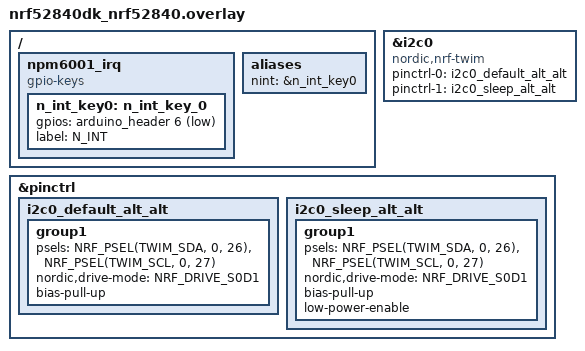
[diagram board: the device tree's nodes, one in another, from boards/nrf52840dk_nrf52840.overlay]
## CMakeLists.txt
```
#
# Copyright (c) 2022 Nordic Semiconductor
#
# SPDX-License-Identifier: LicenseRef-Nordic-5-Clause
#

cmake_minimum_required(VERSION 3.20.0)

find_package(Zephyr REQUIRED HINTS $ENV{ZEPHYR_BASE})
project(NONE)

# NORDIC SDK APP START
target_sources(app PRIVATE
  src/main.c
)
# NORDIC SDK APP END

target_sources_ifdef(CONFIG_SHELL
  app PRIVATE src/sample_shell_cmds.c)
```

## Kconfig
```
#
# Copyright (c) 2022 Nordic Semiconductor ASA
#
# SPDX-License-Identifier: LicenseRef-Nordic-5-Clause
#

menu "Zephyr Kernel"
source "Kconfig.zephyr"
endmenu

menu "nPM6001 sample options"
module = MAIN
module-str = Sample application
source "${ZEPHYR_BASE}/subsys/logging/Kconfig.template.log_config"
endmenu
```

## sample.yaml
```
sample:
  description: nPM6001 sample
  name: npm6001
common:
  integration_platforms:
      - nrf52840dk_nrf52840
      - nrf52dk_nrf52832
      - nrf5340dk_nrf5340_cpuapp
      - nrf5340dk_nrf5340_cpuapp_ns
  platform_allow: nrf52840dk_nrf52840 nrf52dk_nrf52832
    nrf5340dk_nrf5340_cpuapp nrf5340dk_nrf5340_cpuapp_ns
  tags: npm6001 ci_build

tests:
  sample.app_npm6001:
    build_only: true
  sample.app_npm6001_loopback:
    build_only: false
    harness: console
    harness_config:
      ordered: false
      regex:
        - ".*nPM6001 successfully initialized..*"
      type: multi_line
    extra_args: CONFIG_TEST=y
    integration_platforms:
        - nrf52840dk_nrf52840
        - nrf5340dk_nrf5340_cpuapp
```

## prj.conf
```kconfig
#
# Copyright (c) 2022 Nordic Semiconductor
#
# SPDX-License-Identifier: LicenseRef-Nordic-5-Clause
#

# Enable I2C ("TWI")
CONFIG_I2C=y

# Enable nPM6001 library
CONFIG_LIB_NPM6001=y
# Needed for certain nPM6001-EK revisions
CONFIG_LIB_NPM6001_C3_WORKAROUND=y

# Enable logging
CONFIG_LOG=y

# Enable Shell
CONFIG_SHELL=y

# Enable DK LED and Buttons library
CONFIG_DK_LIBRARY=y
CONFIG_GPIO=y
```

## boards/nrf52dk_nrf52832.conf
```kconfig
#
# Copyright (c) 2022 Nordic Semiconductor
#
# SPDX-License-Identifier: LicenseRef-Nordic-5-Clause
#

# Disable Shell
# (nRF52-DK not suitable for using COM port and external power supply simultaneously)
CONFIG_SHELL=n
```

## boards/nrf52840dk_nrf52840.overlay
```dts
i2c0: &i2c0 {
	compatible = "nordic,nrf-twim";
	status = "okay";

	pinctrl-0 = <&i2c0_default_alt_alt>;
	pinctrl-1 = <&i2c0_sleep_alt_alt>;
	pinctrl-names = "default", "sleep";
};

&pinctrl {
	i2c0_default_alt_alt: i2c0_default_alt_alt {
		group1 {
			psels = <NRF_PSEL(TWIM_SDA, 0, 26)>,
				<NRF_PSEL(TWIM_SCL, 0, 27)>;
			nordic,drive-mode = <NRF_DRIVE_S0D1>;
			bias-pull-up;
		};
	};

	i2c0_sleep_alt_alt: i2c0_sleep_alt_alt {
		group1 {
			psels = <NRF_PSEL(TWIM_SDA, 0, 26)>,
				<NRF_PSEL(TWIM_SCL, 0, 27)>;
			nordic,drive-mode = <NRF_DRIVE_S0D1>;
			bias-pull-up;
			low-power-enable;
		};
	};
};

/ {
	npm6001_irq {
		compatible = "gpio-keys";
		n_int_key0: n_int_key_0 {
			gpios = <&arduino_header 6 (GPIO_PULL_UP | GPIO_ACTIVE_LOW)>;	/* D0 */
			label = "N_INT";
		};
	};

	aliases {
		nint = &n_int_key0;
	};
};
```

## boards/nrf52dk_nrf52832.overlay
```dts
&i2c0 {
	compatible = "nordic,nrf-twim";
	status = "okay";

	pinctrl-0 = <&i2c0_default_alt>;
	pinctrl-1 = <&i2c0_sleep_alt>;
	pinctrl-names = "default", "sleep";
	clock-frequency = <I2C_BITRATE_STANDARD>;
};

&pinctrl {
	i2c0_default_alt: i2c0_default_alt {
		group1 {
			psels = <NRF_PSEL(TWIM_SDA, 0, 26)>,
				<NRF_PSEL(TWIM_SCL, 0, 27)>;
			bias-pull-up;
		};
	};

	i2c0_sleep_alt: i2c0_sleep_alt {
		group1 {
			psels = <NRF_PSEL(TWIM_SDA, 0, 26)>,
				<NRF_PSEL(TWIM_SCL, 0, 27)>;
			bias-pull-up;
			low-power-enable;
		};
	};
};

/ {
	npm6001_irq {
		compatible = "gpio-keys";
		n_int: n_int_0 {
			gpios = <&arduino_header 6 (GPIO_PULL_UP | GPIO_ACTIVE_LOW)>;	/* D0 */
			label = "N_INT";
		};
	};
};
```

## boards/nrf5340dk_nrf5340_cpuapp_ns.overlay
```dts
&i2c1 {
	compatible = "nordic,nrf-twim";
	status = "okay";

	pinctrl-0 = <&i2c1_default_alt>;
	pinctrl-1 = <&i2c1_sleep_alt>;
	pinctrl-names = "default", "sleep";
	clock-frequency = <I2C_BITRATE_STANDARD>;
};

&pinctrl {
	i2c1_default_alt: i2c1_default_alt {
		group1 {
			psels = <NRF_PSEL(TWIM_SDA, 1, 2)>,
				<NRF_PSEL(TWIM_SCL, 1, 3)>;
			bias-pull-up;
		};
	};

	i2c1_sleep_alt: i2c1_sleep_alt {
		group1 {
			psels = <NRF_PSEL(TWIM_SDA, 1, 2)>,
				<NRF_PSEL(TWIM_SCL, 1, 3)>;
			bias-pull-up;
			low-power-enable;
		};
	};
};

/ {
	npm6001_irq {
		compatible = "gpio-keys";
		n_int: n_int_0 {
			gpios = <&arduino_header 6 (GPIO_PULL_UP | GPIO_ACTIVE_LOW)>;	/* D0 */
			label = "N_INT";
		};
	};
};
```

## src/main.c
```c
/*
 * Copyright (c) 2022 Nordic Semiconductor ASA
 *
 * SPDX-License-Identifier: LicenseRef-Nordic-5-Clause
 */

#include <zephyr/kernel.h>
#include <zephyr/device.h>
#include <zephyr/drivers/gpio.h>
#include <zephyr/drivers/i2c.h>
#include <zephyr/logging/log.h>

#include <dk_buttons_and_leds.h>

#include <lib_npm6001.h>

LOG_MODULE_REGISTER(main, CONFIG_MAIN_LOG_LEVEL);

#define LED_INIT_OK DK_LED1
#define LED_BUCK3_ON DK_LED2
#define LED_GPIO_ON DK_LED4

#define BUCK0_DEFAULT_VOLTAGE 3300
#define BUCK1_DEFAULT_VOLTAGE 1200
#define BUCK2_DEFAULT_VOLTAGE 1400
#define BUCK3_DEFAULT_VOLTAGE 500
#define LDO0_DEFAULT_VOLTAGE 2700

static K_SEM_DEFINE(n_int_sem, 0, 1);

static const struct device *i2c_dev = DEVICE_DT_GET(DT_NODELABEL(arduino_i2c));

static const struct gpio_dt_spec n_int = GPIO_DT_SPEC_GET(DT_NODELABEL(n_int), gpios);
static struct gpio_callback n_int_callback;

static uint16_t buck3_voltage;
static bool buck3_enabled;
static bool npm6001_gpio_set;

static int lib_npm6001_platform_init(void)
{
	if (device_is_ready(i2c_dev)) {
		return 0;
	} else {
		return -ENODEV;
	}
}

static int lib_npm6001_twi_read(uint8_t *buf, uint8_t len, uint8_t reg_addr)
{
	if (IS_ENABLED(CONFIG_TEST)) {
		memset(buf, 0, len);
		return 0;
	}

	LOG_DBG("twi_read %d bytes @ 0x%02X", len, reg_addr);

	return i2c_write_read(i2c_dev, LIB_NPM6001_TWI_ADDR,
		&reg_addr, sizeof(reg_addr),
		buf, len);
}

static int lib_npm6001_twi_write(const uint8_t *buf, uint8_t len, uint8_t reg_addr)
{
	struct i2c_msg msgs[] = {
		{.buf = &reg_addr, .len = sizeof(reg_addr), .flags = I2C_MSG_WRITE},
		{.buf = (uint8_t *)buf, .len = len, .flags = I2C_MSG_WRITE | I2C_MSG_STOP},
	};

	if (IS_ENABLED(CONFIG_TEST)) {
		return 0;
	}

	if (len == 1) {
		LOG_DBG("twi_write value 0x%02X @ 0x%02X", *buf, reg_addr);
	} else {
		LOG_DBG("twi_write %d bytes @ 0x%02X", len, reg_addr);
	}

	return i2c_transfer(i2c_dev, &msgs[0], ARRAY_SIZE(msgs), LIB_NPM6001_TWI_ADDR);
}

/**
 * @brief Print sample help message to log
 */
static void print_info_message(void)
{
	LOG_INF("nPM6001 sample");
	LOG_INF("");
	LOG_INF("Button behavior:");
	LOG_INF("  Button 1: Toggle BUCK3 regulator on/off");
	LOG_INF("  Button 2: Increase BUCK3 voltage by 25 mV");
	LOG_INF("  Button 3: Decrease BUCK3 voltage by 25 mV");
	LOG_INF("  Button 4: Toggle nPM6001 GPIO pins");
	LOG_INF("  All four buttons pressed at the same time: Hibernate for 8 seconds");
	LOG_INF("LED behavior:");
	LOG_INF("  LED 1: On after successful initialization");
	LOG_INF("  LED 2: On when BUCK3 is turned on");
	LOG_INF("  LED 4: On when nPM6001 GPIO pins are set");
	LOG_INF("  All four LEDs blinking: an error occurred during initialization");
	LOG_INF("");
	LOG_INF("NOTE: The LEDs will likely appear weak if initialization fails,");
	LOG_INF("due to the default nPM6001 BUCK0 supply voltage being relatively low.");
	LOG_INF("");
}

/**
 * @brief Print shell help message to log
 */
static void print_shell_message(void)
{
	LOG_INF("The shell is currently enabled.");
	LOG_INF("See relevant 'npm6001' root command and assosicated subcommands.");
	LOG_INF("(hint: use the 'tab' character for autocompletion)");
}

/**
 * @brief Callback for button events.
 *
 * @param[in]   button_state  Bitmask containing buttons state.
 * @param[in]   has_changed   Bitmask containing buttons that has
 *                            changed their state.
 */
static void button_handler(uint32_t button_state, uint32_t has_changed)
{
	bool set_voltage = false;
	int err;

	if ((button_state & DK_BTN1_MSK) & has_changed) {
		/* Toggle BUCK3 regulator */
		if (buck3_enabled) {
			err = lib_npm6001_vreg_disable(LIB_NPM6001_BUCK3);
			if (err) {
				LOG_ERR("lib_npm6001_vreg_disable=%d", err);
			} else {
				buck3_enabled = false;
				(void) dk_set_led_off(LED_BUCK3_ON);
			}
		} else {
			err = lib_npm6001_vreg_enable(LIB_NPM6001_BUCK3);
			if (err) {
				LOG_ERR("lib_npm6001_vreg_enable=%d", err);
			} else {
				buck3_enabled = true;
				(void) dk_set_led_on(LED_BUCK3_ON);
			}
		}
	}

	if ((button_state & DK_BTN2_MSK) & has_changed) {
		/* Increase voltage by 25 mV */
		buck3_voltage += 25;
		set_voltage = true;
	}

	if ((button_state & DK_BTN3_MSK) & has_changed) {
		/* Decrease voltage by 25 mV */
		buck3_voltage -= 25;
		set_voltage = true;
	}

	if ((button_state & DK_BTN4_MSK) & has_changed) {
		const enum lib_npm6001_gpio gpio_pins[] = {
			LIB_NPM6001_GPIO0,
			LIB_NPM6001_GPIO1,
			LIB_NPM6001_GPIO2,
		};

		/* Toggle nPM6001 GPIO pins */
		for (int i = 0; i < ARRAY_SIZE(gpio_pins); ++i) {
			if (npm6001_gpio_set) {
				err = lib_npm6001_gpio_clr(gpio_pins[i]);
				if (err) {
					LOG_ERR("lib_npm6001_gpio_set=%d", err);
				}
			} else {
				err = lib_npm6001_gpio_set(gpio_pins[i]);
				if (err) {
					LOG_ERR("lib_npm6001_gpio_set=%d", err);
				}
			}
		}

		if (npm6001_gpio_set) {
			npm6001_gpio_set = false;
			(void) dk_set_led_off(LED_GPIO_ON);
		} else {
			npm6001_gpio_set = true;
			(void) dk_set_led_on(LED_GPIO_ON);
		}
	}

	if (button_state == DK_ALL_BTNS_MSK) {
		/* Hibernate for 8 seconds (= 2 ticks) */
		err = lib_npm6001_hibernate(2);
		if (err) {
			LOG_ERR("lib_npm6001_hibernate=%d", err);
		}
	}

	if (set_voltage) {
		buck3_voltage =
			CLAMP(buck3_voltage, LIB_NPM6001_BUCK3_MINV, LIB_NPM6001_BUCK3_MAXV);
		err = lib_npm6001_vreg_voltage_set(LIB_NPM6001_BUCK3, buck3_voltage);
		if (err) {
			LOG_ERR("lib_npm6001_vreg_voltage_set=%d", err);
		}
	}
}

static void n_int_irq_handler(const struct device *port,
					struct gpio_callback *cb,
					gpio_port_pins_t pins)
{
	k_sem_give(&n_int_sem);
}

/**
 * @brief Function for initializing LEDs and Buttons.
 */
static int configure_dk_gpio(void)
{
	int err;

	err = dk_buttons_init(button_handler);
	if (err) {
		LOG_ERR("dk_buttons_init=%d", err);
		return err;
	}

	err = dk_leds_init();
	if (err) {
		LOG_ERR("dk_leds_init=%d", err);
		return err;
	}

	return 0;
}

/**
 * @brief Function for initializing nPM6001 specific GPIO.
 */
static int configure_npm6001_gpio(void)
{
	int err;

	err = gpio_pin_configure_dt(&n_int, GPIO_INPUT);
	if (err) {
		LOG_ERR("gpio_pin_configure_dt=%d", err);
		return err;
	}

	gpio_init_callback(&n_int_callback, n_int_irq_handler, BIT(n_int.pin));

	err = gpio_add_callback(n_int.port, &n_int_callback);
	if (err) {
		LOG_ERR("gpio_add_callback=%d", err);
		return err;
	}

	err = gpio_pin_interrupt_configure_dt(&n_int, GPIO_INT_EDGE_TO_ACTIVE);
	if (err) {
		LOG_ERR("gpio_pin_interrupt_configure_dt=%d", err);
		return err;
	}

	return 0;
}

/**
 * @brief Function for initializing nPM6001 PMIC.
 */
static int configure_npm6001(void)
{
	const struct lib_npm6001_platform ncs_hw_funcs = {
		.lib_npm6001_platform_init = lib_npm6001_platform_init,
		.lib_npm6001_twi_read = lib_npm6001_twi_read,
		.lib_npm6001_twi_write = lib_npm6001_twi_write,
	};
	int err;

	err = lib_npm6001_init(&ncs_hw_funcs);
	if (err) {
		LOG_ERR("lib_npm6001_init=%d", err);
		return err;
	}

	/* Enable pull-downs on mode pins in case they aren't connected to anything.
	 * Note: this will cause an added power drain when the mode pins are actually pulled high.
	 */
	const struct lib_npm6001_mode_pin_cfg pin_cfg = {
		.pad_type = LIB_NPM6001_MODE_PIN_CFG_PAD_TYPE_CMOS,
		.pulldown = LIB_NPM6001_MODE_PIN_CFG_PULLDOWN_ENABLED,
	};
	const enum lib_npm6001_mode_pin mode_pins[] = {
		LIB_NPM6001_BUCK_PIN_MODE0,
		LIB_NPM6001_BUCK_PIN_MODE1,
		LIB_NPM6001_BUCK_PIN_MODE2,
	};

	for (int i = 0; i < ARRAY_SIZE(mode_pins); ++i) {
		err = lib_npm6001_mode_pin_cfg(mode_pins[i], &pin_cfg);
		if (err) {
			LOG_ERR("lib_npm6001_mode_pin_cfg(%d)=%d", mode_pins[i], err);
			return err;
		}
	}

	/* Enable BUCK_MODE1 pin for BUCK1 */
	err = lib_npm6001_vreg_mode_pin_enable(LIB_NPM6001_BUCK1, LIB_NPM6001_BUCK_PIN_MODE1);
	if (err) {
		LOG_ERR("lib_npm6001_vreg_mode_pin_enable=%d", err);
		return err;
	}

	/* Set BUCK0 voltage */
	err = lib_npm6001_vreg_voltage_set(LIB_NPM6001_BUCK0, BUCK0_DEFAULT_VOLTAGE);
	if (err) {
		LOG_ERR("lib_npm6001_vreg_voltage_set=%d", err);
		return err;
	}

	/* Set BUCK1 voltage */
	err = lib_npm6001_vreg_voltage_set(LIB_NPM6001_BUCK1, BUCK1_DEFAULT_VOLTAGE);
	if (err) {
		LOG_ERR("lib_npm6001_vreg_voltage_set=%d", err);
		return err;
	}

	/* Set BUCK1 voltage */
	err = lib_npm6001_vreg_voltage_set(LIB_NPM6001_BUCK2, BUCK2_DEFAULT_VOLTAGE);
	if (err) {
		LOG_ERR("lib_npm6001_vreg_voltage_set=%d", err);
		return err;
	}

	/* Set BUCK3 voltage */
	buck3_voltage = BUCK3_DEFAULT_VOLTAGE;
	err = lib_npm6001_vreg_voltage_set(LIB_NPM6001_BUCK3, buck3_voltage);
	if (err) {
		LOG_ERR("lib_npm6001_vreg_voltage_set=%d", err);
		return err;
	}

	/* Enable BUCK3. Unlike BUCK0, BUCK1, and BUCK2, this is not an always-on regulator. */
	err = lib_npm6001_vreg_enable(LIB_NPM6001_BUCK3);
	if (err) {
		LOG_ERR("lib_npm6001_vreg_enable=%d", err);
		return err;
	}

	buck3_enabled = true;

	/* Set LDO0 voltage */
	err = lib_npm6001_vreg_voltage_set(LIB_NPM6001_LDO0, LDO0_DEFAULT_VOLTAGE);
	if (err) {
		LOG_ERR("lib_npm6001_vreg_voltage_set=%d", err);
		return err;
	}

	/* Enable LDO0. */
	err = lib_npm6001_vreg_enable(LIB_NPM6001_LDO0);
	if (err) {
		LOG_ERR("lib_npm6001_vreg_enable=%d", err);
		return err;
	}

	/* Enable LDO1. This regulator has fixed 1.8V voltage. */
	err = lib_npm6001_vreg_enable(LIB_NPM6001_LDO1);
	if (err) {
		LOG_ERR("lib_npm6001_vreg_enable=%d", err);
		return err;
	}

	const struct lib_npm6001_gpio_cfg gpio_cfg = {
		.direction = LIB_NPM6001_GPIO_CFG_DIRECTION_OUTPUT,
		.input = LIB_NPM6001_GPIO_CFG_INPUT_DISABLED,
		.pulldown = LIB_NPM6001_GPIO_CFG_PULLDOWN_DISABLED,
		.drive = LIB_NPM6001_GPIO_CFG_DRIVE_NORMAL,
		.sense = LIB_NPM6001_GPIO_CFG_SENSE_LOW,
	};
	const enum lib_npm6001_gpio gpio_pins[] = {
		LIB_NPM6001_GPIO0,
		LIB_NPM6001_GPIO1,
		LIB_NPM6001_GPIO2,
	};

	/* Configure nPM6001 GPIO pins as outputs */
	for (int i = 0; i < ARRAY_SIZE(gpio_pins); ++i) {
		err = lib_npm6001_gpio_cfg(gpio_pins[i], &gpio_cfg);
		if (err) {
			LOG_ERR("lib_npm6001_gpio_cfg=%d", err);
			return err;
		}
	}

	npm6001_gpio_set = false;

	/* Enable overcurrent interrupts */
	const enum lib_npm6001_int interrupts[] = {
		LIB_NPM6001_INT_BUCK0_OVERCURRENT,
		LIB_NPM6001_INT_BUCK1_OVERCURRENT,
		LIB_NPM6001_INT_BUCK2_OVERCURRENT,
		LIB_NPM6001_INT_BUCK3_OVERCURRENT,
	};

	for (int i = 0; i < ARRAY_SIZE(interrupts); ++i) {
		err = lib_npm6001_int_enable(interrupts[i]);
		if (err) {
			LOG_ERR("lib_npm6001_int_enable(%d)=%d", (int) interrupts[i], err);
			return err;
		}
	}

	return 0;
}

void main(void)
{
	int err;

	print_info_message();

	if (IS_ENABLED(CONFIG_SHELL)) {
		print_shell_message();
	}

	/* With this hardware configuration, the nPM6001 powers up the nRF5x SoC and associated
	 * Development Kit circuitry. Having a generous delay allows all voltages to settle before
	 * communicating with the nPM6001 EK via the voltage level shifters.
	 */
	k_sleep(K_SECONDS(1));

	err = configure_dk_gpio();
	if (err) {
		LOG_ERR("configure_dk_gpio=%d", err);
		goto init_error;
	}

	err = configure_npm6001_gpio();
	if (err) {
		LOG_ERR("configure_npm6001_gpio=%d", err);
		goto init_error;
	}

	err = configure_npm6001();
	if (err) {
		LOG_ERR("configure_npm6001=%d", err);
		goto init_error;
	}

	LOG_INF("nPM6001 successfully initialized.");

	err = dk_set_led_on(LED_INIT_OK);
	if (err) {
		LOG_ERR("dk_set_led_on=%d", err);
		goto init_error;
	}

	err = dk_set_led_on(LED_BUCK3_ON);
	if (err) {
		LOG_ERR("dk_set_led_on=%d", err);
		goto init_error;
	}

	/* Wait for interrupts */
	while (true) {
		k_sem_take(&n_int_sem, K_FOREVER);

		/* N_INT pin will be active as long as there is one or more unread interrupts */
		do {
			enum lib_npm6001_int int_src;

			err = lib_npm6001_int_read(&int_src);
			if (err) {
				LOG_ERR("lib_npm6001_int_read=%d", err);
				break;
			}

			switch (int_src) {
			case LIB_NPM6001_INT_THERMAL_WARNING:
				LOG_WRN("Thermal warning interrupt");
				break;
			case LIB_NPM6001_INT_BUCK0_OVERCURRENT:
				LOG_WRN("BUCK0 overcurrent interrupt");
				break;
			case LIB_NPM6001_INT_BUCK1_OVERCURRENT:
				LOG_WRN("BUCK1 overcurrent interrupt");
				break;
			case LIB_NPM6001_INT_BUCK2_OVERCURRENT:
				LOG_WRN("BUCK2 overcurrent interrupt");
				break;
			case LIB_NPM6001_INT_BUCK3_OVERCURRENT:
				LOG_WRN("BUCK3 overcurrent interrupt");
				break;
			default:
				LOG_ERR("Unknown interrupt: %d", int_src);
				break;
			}
		} while (gpio_pin_get_dt(&n_int));
	}

	return;

init_error:

	while (true) {
		(void) dk_set_leds(DK_ALL_LEDS_MSK);
		k_msleep(250);
		(void) dk_set_leds(DK_NO_LEDS_MSK);
		k_msleep(250);
	}
}
```

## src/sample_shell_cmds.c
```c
/*
 * Copyright (c) 2022 Nordic Semiconductor ASA
 *
 * SPDX-License-Identifier: LicenseRef-Nordic-5-Clause
 */

#include <stdlib.h>

#include <zephyr/kernel.h>
#include <shell/shell.h>
#include <zephyr/device.h>
#include <zephyr/drivers/i2c.h>

#include <lib_npm6001.h>
#include <npm6001/npm6001.h>

/**
 * @brief Register name and address pairs, used to enable tab-completion for register shell command.
 */
struct reg_name_addr_pair {
	const char *name;
	uint8_t addr;
};

static const struct reg_name_addr_pair registers[] = {
#define X(_reg_name) {.name = STRINGIFY(_reg_name), .addr = offsetof(NRF_DIGITAL_Type, _reg_name)},
	LIB_NPM6001_REGISTER_NAME_LIST
#undef X
};

static const struct device *i2c_dev = DEVICE_DT_GET(DT_NODELABEL(arduino_i2c));

static uint8_t twi_read(const struct shell *sh, uint8_t reg_addr)
{
	uint8_t reg_val = 0;
	int err;

	err = i2c_write_read(i2c_dev, LIB_NPM6001_TWI_ADDR,
		&reg_addr, sizeof(reg_addr),
		&reg_val, sizeof(reg_val));

	if (err) {
		shell_error(sh, "TWI read error");
	}

	return reg_val;
}

static void twi_write(const struct shell *sh, uint8_t reg_addr, uint8_t reg_val)
{
	struct i2c_msg msgs[] = {
		{.buf = &reg_addr, .len = sizeof(reg_addr), .flags = I2C_MSG_WRITE},
		{.buf = &reg_val, .len = sizeof(reg_val), .flags = I2C_MSG_WRITE | I2C_MSG_STOP},
	};
	int err;

	err = i2c_transfer(i2c_dev, &msgs[0], ARRAY_SIZE(msgs), LIB_NPM6001_TWI_ADDR);
	if (err) {
		shell_error(sh, "TWI write error");
	}
}

static int cmd_reg_named(const struct shell *sh, size_t argc, char **argv)
{
	const struct reg_name_addr_pair *reg = NULL;
	uint8_t reg_val;

	if (argc == 0) {
		shell_error(sh, "Invalid argument count");
		return -ENOEXEC;
	}

	if (strcmp(argv[0], "reg") == 0) {
		shell_print(sh, "Please specify which register to read or write");
		shell_print(sh, "(hint: use 'tab' key for autocompletion)");
		return 0;
	}

	for (int i = 0; i < ARRAY_SIZE(registers); ++i) {
		if (strcmp(argv[0], registers[i].name) == 0) {
			reg = &registers[i];
			break;
		}
	}

	if (reg == NULL) {
		shell_warn(sh, "Register name not found");
		return 0;
	}

	if (argc > 1) {
		/* Write register */
		if (strncmp(argv[1], "0b", 2) == 0 && strlen(argv[1]) > 2) {
			/* Skip "0b" for base 2 */
			reg_val = (uint8_t) strtol(&argv[1][2], NULL, 2);
		} else {
			/* strtol figures out base */
			reg_val = (uint8_t) strtol(argv[1], NULL, 0);
		}

		shell_print(sh, "Writing 0x%02X to %s", reg_val, reg->name);
		twi_write(sh, reg->addr, reg_val);
	} else {
		/* Read register */
		shell_print(sh, "%s=0x%02X", reg->name, twi_read(sh, reg->addr));
	}

	return 0;
}

#define X(_reg_name) SHELL_CMD_ARG(_reg_name, NULL, "[Value]", cmd_reg_named, 1, 1),
SHELL_STATIC_SUBCMD_SET_CREATE(npm6001_reg_cmds,
	LIB_NPM6001_REGISTER_NAME_LIST
	SHELL_SUBCMD_SET_END
);
#undef X

static int cmd_vreg(const struct shell *sh, size_t argc, char **argv)
{
	enum lib_npm6001_vreg_mode mode = LIB_NPM6001_MODE_ULP;
	enum lib_npm6001_vreg regulator;
	uint16_t voltage = 0;
	uint16_t v_min;
	uint16_t v_max;
	bool set_mode = false;
	bool set_voltage = false;
	bool turn_on = false;
	bool turn_off = false;
	int err;

	if (argc == 1) {
		shell_print(sh, "Usage: ~$ npm6001 vreg REGULATOR [MODE] [VOLTAGE mV]");
		shell_print(sh, "example, set output voltage: ~$ npm6001 vreg BUCK3 2500");
		shell_print(sh, "example, turn off: ~$ npm6001 vreg BUCK3 off");
		shell_print(sh, "example, set PWM mode: ~$ npm6001 vreg BUCK2 pwm");
		return 0;
	}

	if (strcmp(argv[0], "BUCK0") == 0) {
		regulator = LIB_NPM6001_BUCK0;
	} else if (strcmp(argv[0], "BUCK1") == 0) {
		regulator = LIB_NPM6001_BUCK1;
	} else if (strcmp(argv[0], "BUCK2") == 0) {
		regulator = LIB_NPM6001_BUCK2;
	} else if (strcmp(argv[0], "BUCK3") == 0) {
		regulator = LIB_NPM6001_BUCK3;
	} else if (strcmp(argv[0], "LDO0") == 0) {
		regulator = LIB_NPM6001_LDO0;
	} else if (strcmp(argv[0], "LDO1") == 0) {
		regulator = LIB_NPM6001_LDO1;
	} else {
		shell_print(sh, "Please specify valid regulator to adjust");
		shell_print(sh, "(hint: use 'tab' key for autocompletion)");
		return 0;
	}

	for (int i = 1; i < argc; ++i) {
		if (strcmp(argv[i], "ON") == 0 || strcmp(argv[i], "on") == 0) {
			turn_on = true;
			break;
		}
		if (strcmp(argv[i], "OFF") == 0 || strcmp(argv[i], "off") == 0) {
			turn_off = true;
			break;
		}
		if (strcmp(argv[i], "0") == 0) {
			/* Interpret 0 mV as shut off */
			turn_off = true;
			break;
		}

		if (strcmp(argv[i], "ULP") == 0 || strcmp(argv[i], "ulp") == 0) {
			set_mode = true;
			mode = LIB_NPM6001_MODE_ULP;
		} else if (strcmp(argv[i], "PWM") == 0 || strcmp(argv[i], "pwm") == 0) {
			set_mode = true;
			mode = LIB_NPM6001_MODE_PWM;
		} else {
			set_voltage = true;
			voltage = strtol(argv[i], NULL, 0);
			if (voltage == 0) {
				shell_warn(sh, "Unexpected parameter: %s", argv[i]);
				return 0;
			}
		}
	}

	if (set_voltage && voltage == 0) {
		turn_off = true;
		set_voltage = false;
	} else if (set_voltage) {
		turn_on = true;
	}

	if (turn_off && regulator == LIB_NPM6001_BUCK0) {
		shell_warn(sh, "BUCK0 cannot be turned off");
		return 0;
	}

	if (set_mode && (regulator == LIB_NPM6001_LDO0 || regulator == LIB_NPM6001_LDO1)) {
		shell_warn(sh, "LDO regulators does not have mode selection");
		set_mode = false;
	}

	if (set_voltage) {
		switch (regulator) {
		case LIB_NPM6001_BUCK0:
			v_min = LIB_NPM6001_BUCK0_MINV;
			v_max = LIB_NPM6001_BUCK0_MAXV;
			break;
		case LIB_NPM6001_BUCK1:
			v_min = LIB_NPM6001_BUCK1_MINV;
			v_max = LIB_NPM6001_BUCK1_MAXV;
			break;
		case LIB_NPM6001_BUCK2:
			v_min = LIB_NPM6001_BUCK2_MINV;
			v_max = LIB_NPM6001_BUCK2_MAXV;
			break;
		case LIB_NPM6001_BUCK3:
			v_min = LIB_NPM6001_BUCK3_MINV;
			v_max = LIB_NPM6001_BUCK3_MAXV;
			break;
		case LIB_NPM6001_LDO0:
			v_min = LIB_NPM6001_LDO0_MINV;
			v_max = LIB_NPM6001_LDO0_MAXV;
			break;
		case LIB_NPM6001_LDO1:
			v_min = LIB_NPM6001_LDO1_MINV;
			v_max = LIB_NPM6001_LDO1_MAXV;
			break;
		default:
			shell_error(sh, "Internal error");
			return 0;
		}

		if (voltage < v_min || voltage > v_max) {
			shell_warn(sh, "Invalid voltage selection. Valid range for %s: %d mV - %d mV",
				argv[0], v_min, v_max);
				return 0;
		}

		if (regulator == LIB_NPM6001_LDO1) {
			/* LDO1 does not have configurable voltage. Only on/off. */
			set_voltage = false;
		}
	}

	if (set_mode) {
		err = lib_npm6001_vreg_buck_mode_set(regulator, mode);
		if (err) {
			shell_warn(sh, "Failed to set mode");
			return 0;
		}

		shell_print(sh, "Successfully set %s mode", argv[0]);
	}

	if (set_voltage) {
		if (regulator == LIB_NPM6001_BUCK3) {
			/* Should turn BUCK3 off while adjusting voltage to prevent overshoot */
			err = lib_npm6001_vreg_disable(regulator);
			if (err) {
				shell_warn(sh, "Failed to disable %s", argv[0]);
			} else {
				turn_on = true;
			}
		}
		err = lib_npm6001_vreg_voltage_set(regulator, voltage);
		if (err == -EINVAL) {
			shell_warn(sh, "Invalid voltage selection");
			return 0;
		} else if (err) {
			shell_warn(sh, "Failed to set voltage");
		} else {
			shell_print(sh, "Successfully set %s voltage", argv[0]);
		}
	}

	if (turn_on) {
		err = lib_npm6001_vreg_enable(regulator);
		if (err) {
			shell_warn(sh, "Failed to enable %s", argv[0]);
		}
	} else if (turn_off) {
		err = lib_npm6001_vreg_disable(regulator);
		if (err == -EINVAL) {
			shell_warn(sh, "%s cannot be disabled", argv[0]);
		} else if (err) {
			shell_warn(sh, "Failed to disable %s", argv[0]);
		} else {
			shell_print(sh, "Successfully disabled %s", argv[0]);
		}
	}

	return 0;
}

SHELL_STATIC_SUBCMD_SET_CREATE(npm6001_vreg_cmds,
	SHELL_CMD_ARG(BUCK0, NULL, "[ULP/PWM] [Voltage] (1800 - 3300 mV)", cmd_vreg, 1, 3),
	SHELL_CMD_ARG(BUCK1, NULL, "[on/off] [ULP/PWM] [Voltage] (700 - 1400 mV)", cmd_vreg, 1, 3),
	SHELL_CMD_ARG(BUCK2, NULL, "[on/off] [ULP/PWM] [Voltage] (1200 - 1400 mV)", cmd_vreg, 1, 3),
	SHELL_CMD_ARG(BUCK3, NULL, "[on/off] [ULP/PWM] [Voltage] (500 - 3300 mV)", cmd_vreg, 1, 3),
	SHELL_CMD_ARG(LDO0, NULL, "[on/off] [Voltage] (1800 - 3300 mV)", cmd_vreg, 1, 3),
	SHELL_CMD_ARG(LDO1, NULL, "[on/off]", cmd_vreg, 1, 3),
	SHELL_SUBCMD_SET_END
);

static int cmd_wd_enable(const struct shell *sh, size_t argc, char **argv)
{
	uint32_t timeout;
	int err;

	if (argc != 2) {
		shell_print(sh, "Usage: ~$ npm6001 watchdog enable [timeout]");
		return 0;
	}

	timeout = strtol(argv[1], NULL, 0);

	err = lib_npm6001_watchdog_enable(timeout);
	if (err == -EINVAL) {
		shell_warn(sh, "Invalid watchdog timeout");
		return 0;
	} else if (err) {
		shell_warn(sh, "Failed to enable watchdog");
	} else {
		shell_print(sh, "Successfully enabled watchdog");
	}

	return 0;
}

static int cmd_wd_disable(const struct shell *sh, size_t argc, char **argv)
{
	int err;

	err = lib_npm6001_watchdog_disable();
	if (err) {
		shell_warn(sh, "Failed to disable watchdog");
	} else {
		shell_print(sh, "Successfully disabled watchdog");
	}

	return 0;
}

static int cmd_wd_kick(const struct shell *sh, size_t argc, char **argv)
{
	int err;

	err = lib_npm6001_watchdog_kick();
	if (err) {
		shell_warn(sh, "Failed to kick watchdog");
	} else {
		shell_print(sh, "Successfully kicked watchdog");
	}

	return 0;
}

SHELL_STATIC_SUBCMD_SET_CREATE(npm6001_wd_cmds,
	SHELL_CMD_ARG(enable, NULL, "[TIMEOUT] (4 second ticks)", cmd_wd_enable, 2, 1),
	SHELL_CMD_ARG(disable, NULL, "", cmd_wd_disable, 1, 1),
	SHELL_CMD_ARG(kick, NULL, "", cmd_wd_kick, 1, 1),
	SHELL_SUBCMD_SET_END
);

static int cmd_int(const struct shell *sh, size_t argc, char **argv)
{
	enum lib_npm6001_int interrupt;
	bool enable;
	int err;

	if (argc < 2) {
		shell_print(sh, "Usage: ~$ npm6001 interrupt TYPE [enable/disable]");
		shell_print(sh, "example: ~$ npm6001 THWARN enable");
		shell_print(sh, "         ~$ npm6001 BUCK1OC disable");
		return 0;
	}

	if (strcmp(argv[0], "THWARN") == 0) {
		interrupt = LIB_NPM6001_INT_THERMAL_WARNING;
	} else if (strcmp(argv[0], "BUCK0OC") == 0) {
		interrupt = LIB_NPM6001_INT_BUCK0_OVERCURRENT;
	} else if (strcmp(argv[0], "BUCK1OC") == 0) {
		interrupt = LIB_NPM6001_INT_BUCK1_OVERCURRENT;
	} else if (strcmp(argv[0], "BUCK2OC") == 0) {
		interrupt = LIB_NPM6001_INT_BUCK2_OVERCURRENT;
	} else if (strcmp(argv[0], "BUCK3OC") == 0) {
		interrupt = LIB_NPM6001_INT_BUCK3_OVERCURRENT;
	} else {
		shell_print(sh, "Please specify valid interrupt to configure");
		shell_print(sh, "(hint: use 'tab' key for autocompletion)");
		return 0;
	}

	if (strcmp(argv[1], "ENABLE") == 0 || strcmp(argv[1], "enable") == 0) {
		enable = true;
	} else if (strcmp(argv[1], "DISABLE") == 0 || strcmp(argv[1], "disable") == 0) {
		enable = false;
	} else {
		shell_warn(sh, "Invalid option");
		return 0;
	}

	if (enable) {
		err = lib_npm6001_int_enable(interrupt);
	} else {
		err = lib_npm6001_int_disable(interrupt);
	}

	if (err) {
		shell_error(sh, "Failed to %s interrupt", enable ? "enable" : "disable");
	} else {
		shell_print(sh, "Successfully %s interrupt", enable ? "enabled" : "disabled");
	}

	return 0;
}

SHELL_STATIC_SUBCMD_SET_CREATE(npm6001_int_cmds,
	SHELL_CMD_ARG(THWARN, NULL, "Thermal warning [enable/disable]", cmd_int, 1, 2),
	SHELL_CMD_ARG(BUCK0OC, NULL, "BUCK0 overcurrent [enable/disable]", cmd_int, 1, 2),
	SHELL_CMD_ARG(BUCK1OC, NULL, "BUCK1 overcurrent [enable/disable]", cmd_int, 1, 2),
	SHELL_CMD_ARG(BUCK2OC, NULL, "BUCK2 overcurrent [enable/disable]", cmd_int, 1, 2),
	SHELL_CMD_ARG(BUCK3OC, NULL, "BUCK3 overcurrent [enable/disable]", cmd_int, 1, 2),
	SHELL_SUBCMD_SET_END
);

static int cmd_hibernate(const struct shell *sh, size_t argc, char **argv)
{
	uint32_t timeout;
	int err;

	if (argc != 2) {
		shell_print(sh, "Usage: ~$ npm6001 hibernate timeout");
		shell_print(sh, "example, 1 hour hibernation: ~$ npm6001 hibernate 900");
		return 0;
	}

	timeout = strtol(argv[1], NULL, 0);

	err = lib_npm6001_hibernate(timeout);
	if (err == -EINVAL) {
		shell_warn(sh, "Invalid hibernation wakeup duration");
		return 0;
	} else if (err) {
		shell_warn(sh, "Failed to enable hibernation mode");
	} else {
		shell_print(sh, "Successfully enabled hibernation mode");
	}

	return 0;
}

SHELL_STATIC_SUBCMD_SET_CREATE(npm6001_cmds,
	SHELL_CMD_ARG(vreg, &npm6001_vreg_cmds, "Voltage regulator control", cmd_vreg, 2, 1),
	SHELL_CMD_ARG(reg, &npm6001_reg_cmds, "Register read/write", NULL, 1, 2),
	SHELL_CMD_ARG(
		watchdog, &npm6001_wd_cmds, "Watchdog enable/disable/kick", cmd_wd_enable, 1, 1),
	SHELL_CMD_ARG(hibernate, NULL, "Hibernate", cmd_hibernate, 1, 1),
	SHELL_CMD_ARG(interrupt, &npm6001_int_cmds, "Interrupt enable/disable", cmd_int, 2, 1),
	SHELL_SUBCMD_SET_END
);

static int cmd_npm6001(const struct shell *sh, size_t argc, char **argv)
{
	shell_help(sh);

	return 0;
}

SHELL_CMD_ARG_REGISTER(npm6001, &npm6001_cmds, "nPM6001 shell commands",
			   cmd_npm6001, 1, 1);
```
